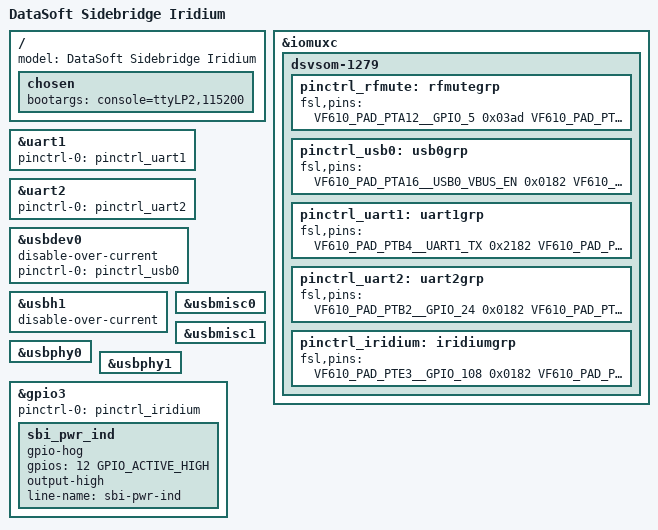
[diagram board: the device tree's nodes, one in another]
/*
 * Copyright 2016 DataSoft Corporation
 *
 * This program is free software; you can redistribute it and/or modify
 * it under the terms of the GNU General Public License as published by
 * the Free Software Foundation; either version 2 of the License, or
 * (at your option) any later version.
 */

/dts-v1/;
#include "dsvsom-1190-sbi.dtsi"

/ {
	model = "DataSoft Sidebridge Iridium";

	chosen {
		bootargs = "console=ttyLP2,115200";
	};

};

&iomuxc {
	dsvsom-1279 {

		pinctrl_rfmute: rfmutegrp {
			fsl,pins = <
				VF610_PAD_PTA12__GPIO_5			0x03ad 	/* GPIO_PB_RF_MUTEN */
				VF610_PAD_PTC6__GPIO_51			0x0182 	/* GPIO_RF_MUTE_STAT_RED_LEDN */
				VF610_PAD_PTC7__GPIO_52			0x0182 	/* GPIO_RF_MUTE_STAT_GRN_LEDN */
				VF610_PAD_PTC8__GPIO_53			0x0182 	/* GPIO_RF_MUTE_STAT_BLU_LEDN */
			>;
		};

		pinctrl_usb0: usb0grp {
			fsl,pins = <
				VF610_PAD_PTA16__USB0_VBUS_EN		0x0182
				VF610_PAD_PTA17__USB0_VBUS_OC		0x0181
				VF610_PAD_PTB23__GPIO_93		0x01ad 	/* GPIO_CONN_USB0_ID */
			>;
		};

		pinctrl_uart1: uart1grp {
			fsl,pins = <
				VF610_PAD_PTB4__UART1_TX		0x2182
				VF610_PAD_PTB5__UART1_RX		0x21ad
			>;
		};

		pinctrl_uart2: uart2grp {
			fsl,pins = <
				VF610_PAD_PTB2__GPIO_24			0x0182 	/* GPIO_RX232_EN */
				VF610_PAD_PTD0__UART2_TX		0x2182
				VF610_PAD_PTD1__UART2_RX		0x21ad
			>;
		};

		pinctrl_iridium: iridiumgrp {
			fsl,pins = <
				VF610_PAD_PTE3__GPIO_108		0x0182  /* GPIO_SBI_PWR_IND */
				VF610_PAD_PTE4__GPIO_109		0x01ad  /* GPIO_PGOOD_RADIO_IN */
				VF610_PAD_PTE6__GPIO_111		0x0182  /* GPIO_SBI_PWR_SRC */
				VF610_PAD_PTE13__GPIO_118		0x0182  /* GPIO_SBI_WAKE */
				VF610_PAD_PTE14__GPIO_119		0x0182  /* GPIO_SBI_SPARE0 */
				VF610_PAD_PTE22__GPIO_127		0x0182  /* GPIO_SBI_SPARE1 */
			>;
		};
	};
};

&uart1 {
	pinctrl-names = "default";
	pinctrl-0 = <&pinctrl_uart1>;
	status = "okay";
};

&uart2 {
	pinctrl-names = "default";
	pinctrl-0 = <&pinctrl_uart2>;
	status = "okay";
};

&usbdev0 {
	disable-over-current;
	pinctrl-names = "default";
	pinctrl-0 = <&pinctrl_usb0>;
	status = "okay";
};

&usbh1 {
	disable-over-current;
	status = "okay";
};

&usbmisc0 {
	status = "okay";
};

&usbmisc1 {
	status = "okay";
};

&usbphy0 {
	status = "okay";
};

&usbphy1 {
	status = "okay";
};

&gpio3 {
	pinctrl-names = "default";
	pinctrl-0 = <&pinctrl_iridium>;

	sbi_pwr_ind {
		gpio-hog;
		gpios = <12 GPIO_ACTIVE_HIGH>;
		output-high;
		line-name = "sbi-pwr-ind";
	};
};
